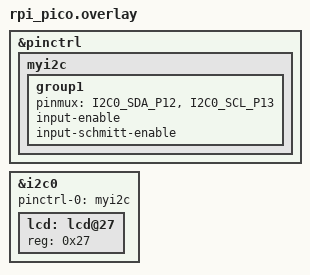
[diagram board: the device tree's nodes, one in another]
&pinctrl {

        myi2c: myi2c {
            group1 {
                pinmux = <I2C0_SDA_P12>, <I2C0_SCL_P13>;
                input-enable;
                input-schmitt-enable;
            };
        };
};

&i2c0 {
    status = "okay";
    pinctrl-0 = <&myi2c>;

    lcd: lcd@27 {
        reg = <0x27>;
    };
};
